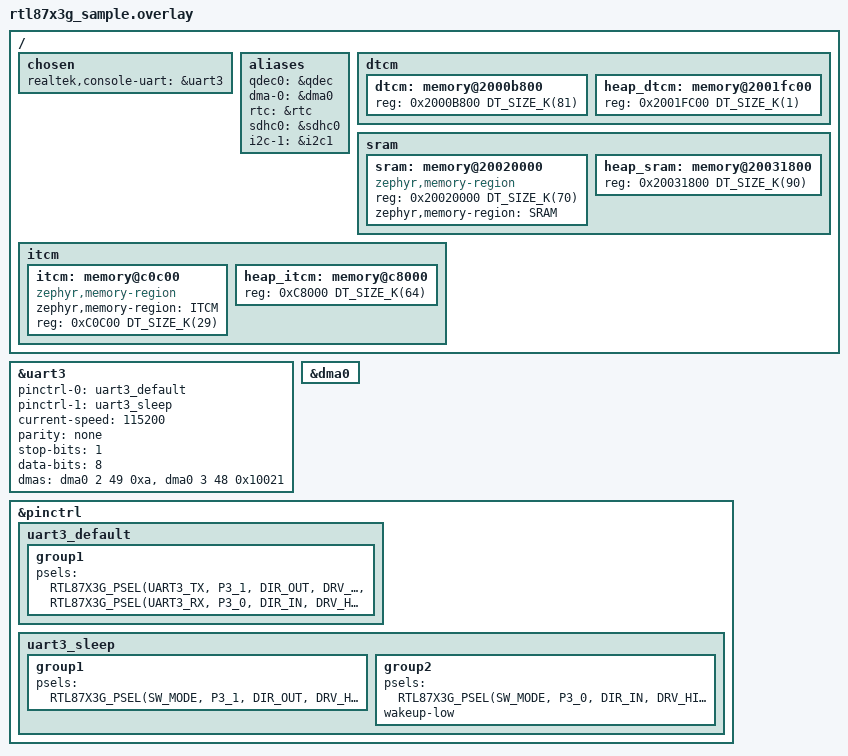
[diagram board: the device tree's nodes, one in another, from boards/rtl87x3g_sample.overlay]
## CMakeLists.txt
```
#
# Copyright (c) 2026, Realtek Semiconductor Corporation
#
# SPDX-License-Identifier: LicenseRef-Realtek-5-Clause
#

message(STATUS "CMAKELIST FOLDER: ${CMAKE_CURRENT_SOURCE_DIR}")

cmake_minimum_required(VERSION 3.20.0)

#===========version generation===========
include(${CMAKE_CURRENT_SOURCE_DIR}/../../cmake/version_generate.cmake)
generate_version()
#===========version generation===========
#===========post build===========
# post build should be called before find_package
include(${CMAKE_CURRENT_SOURCE_DIR}/../../cmake/post_build.cmake)
rtk_post_build()
#===========post build===========

find_package(Zephyr REQUIRED HINTS $ENV{ZEPHYR_BASE})
project(bt_pan_demo)

FILE(GLOB app_sources src/*.c src/pan_test/*.c src/pan_test/https/*.c)
target_sources(app PRIVATE
  ${app_sources}
  )

set(sources
   ${ZEPHYR_REALTEK_APP_MODULE_DIR}/common/console/transport/console_uart.c
   )

set(headers
    #header files from app
	  src/
    #header files from libs
    ${ZEPHYR_REALTEK_APP_MODULE_DIR}/../modules/hal/realtek/rtl87x3g/subsys/audio/inc
    ${ZEPHYR_REALTEK_APP_MODULE_DIR}/../modules/hal/realtek/rtl87x3g/subsys/console/inc
    ${ZEPHYR_REALTEK_APP_MODULE_DIR}/../modules/hal/realtek/rtl87x3g/subsys/lwip/src/arch
    ${ZEPHYR_REALTEK_APP_MODULE_DIR}/../modules/hal/realtek/rtl87x3g/subsys/lwip/src
    ${ZEPHYR_REALTEK_APP_MODULE_DIR}/../modules/hal/realtek/rtl87x3g/subsys/lwip/
    ${ZEPHYR_REALTEK_APP_MODULE_DIR}/../modules/hal/realtek/rtl87x3g/subsys/mbedtls/include/mbedtls
    ${ZEPHYR_REALTEK_APP_MODULE_DIR}/common/console/transport
    ${ZEPHYR_REALTEK_APP_MODULE_DIR}/samples/bt_pan_demo
    )  

foreach(header ${headers})
    if(EXISTS ${header})
        zephyr_include_directories(${header})
    else()
        message(FATAL_ERROR "header file directory does not exist: ${header}. Current cmakelist: ${CMAKE_CURRENT_SOURCE_DIR}")
    endif()
endforeach()

foreach(src ${sources})
    if(EXISTS ${src})
        target_sources(app PRIVATE ${src})
    else()
        message(FATAL_ERROR "source file does not exist: ${src}. Current cmakelist: ${CMAKE_CURRENT_SOURCE_DIR}")
    endif()
endforeach()
  
target_precompile_headers(app PUBLIC
	          ${CMAKE_CURRENT_SOURCE_DIR}/src/app_flags.h
			  )

target_include_directories(app PRIVATE src)
```

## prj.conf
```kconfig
# nothing here
CONFIG_SERIAL=y
CONFIG_UART_ASYNC_API=y
CONFIG_REALTEK_SUBSYS_SYSM=y
CONFIG_REALTEK_SUBSYS_CONSOLE=y
CONFIG_REALTEK_SUBSYS_REMOTE=y
CONFIG_REALTEK_SUBSYS_BTM=y
CONFIG_REALTEK_SUBSYS_AUDIO=y
CONFIG_REALTEK_SUBSYS_LWIP=y
CONFIG_REALTEK_SUBSYS_MBEDTLS=y
CONFIG_NEWLIB_LIBC=y
CONFIG_HEAP_MEM_POOL_SIZE=1024
```

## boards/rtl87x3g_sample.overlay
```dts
/*
 * Copyright(c) 2024, Realtek Semiconductor Corporation.
 *
 * SPDX-License-Identifier: Apache-2.0
 */

#include <zephyr/dt-bindings/gpio/realtek-rtl87x3g-gpio.h>
#include <zephyr/dt-bindings/pinctrl/rtl87x3g-pinctrl.h>

/ {
    chosen {
        /* Route the RTK console transport onto uart3 through the Zephyr async
         * UART driver. Change this phandle to move the console to any UART. */
        realtek,console-uart = &uart3;
    };
};

&uart3 {
    pinctrl-0 = <&uart3_default>;
    pinctrl-1 = <&uart3_sleep>;
    pinctrl-names = "default", "sleep";
    status = "okay";
    current-speed = <115200>;
    parity = "none";
    stop-bits = "1";
    data-bits = <8>;
    dmas = <&dma0 2 49 0xa>, <&dma0 3 48 0x10021>;
    dma-names = "rx", "tx";
};
 
&dma0 {
    status = "okay";
};
 
&pinctrl
{
    uart3_default:uart3_default {
        group1 {
            psels = <RTL87X3G_PSEL(UART3_TX, P3_1, DIR_OUT, DRV_HIGH, PULL_UP)>,
            <RTL87X3G_PSEL(UART3_RX, P3_0, DIR_IN, DRV_HIGH, PULL_UP)>;
        };
    };
 
    uart3_sleep:uart3_sleep {
        group1 {
            psels = <RTL87X3G_PSEL(SW_MODE, P3_1, DIR_OUT, DRV_HIGH, PULL_UP)>;
        };
        group2 {
            psels = <RTL87X3G_PSEL(SW_MODE, P3_0, DIR_IN, DRV_HIGH, PULL_UP)>;
            wakeup-low;
        };
    };
};

/*delete-node only support nodes with lable */
/delete-node/ &dtcm;
/delete-node/ &heap_dtcm;
/delete-node/ &sram;
/delete-node/ &heap_sram;
/delete-node/ &itcm;
/delete-node/ &heap_itcm;
/delete-node/ &dsp_share_ram;

/ {
	aliases {
		qdec0 = &qdec;
		dma-0 = &dma0;
		rtc = &rtc;
		sdhc0 = &sdhc0;
		i2c-1 = &i2c1;
    };


	
	/* DTCM addr: 0x20000000~0x20020000, total size: 128KByte.
	 * The front 46Kbyte was taken by RTK internal.
	 * If users wants to increase global variables and zephyr static heap,
	 * please follow the steps:
	 * 1. increase dtcm size value "reg = <0x2000B800 DT_SIZE_K(NEW_SIZE)>"
	 * 2. modify heap_dtcm addr label "heap_dtcm: memory@NEW_ADDR"
	 * 3. modify heap_dtcm reg addr "reg = <NEW_ADDR DT_SIZE_K(NEW_SIZE)>"
	 * 4. decrease heap_dtcm size value "reg = <NEW_ADDR DT_SIZE_K(NEW_SIZE)>"
	 * Warning: 
	 * 1. the dtcm address should NOT modified!
	 * 2. the dtcm plus heap_dtcm size should NOT exceed 82KByte!
	 */
	dtcm {
		dtcm: memory@2000b800 {
			device_type = "dtcm region";
			reg = <0x2000B800 DT_SIZE_K(81)>;
		};
		heap_dtcm: memory@2001fc00 {
			device_type = "heap dtcm region";
			reg = <0x2001FC00 DT_SIZE_K(1)>;
		};
	};
	/* sram addr: 0x20020000~0x20048000, total size: 160KByte.
	 * call zephyr_code_relocate(FILES xxx.x LOCATION SRAM) at cmakelist could relocate variables on sram. 
	 * for more information, please refer to https://docs.zephyrproject.org/latest/kernel/code-relocation.html
	 * If users wants to increase sram size, please follow the steps:
	 * 1. increase sram size value "reg = <0x20020000 DT_SIZE_K(NEW_SIZE)>"
	 * 2. modify heap_sram addr label "heap_sram: memory@NEW_ADDR"
	 * 3. modify heap_sram reg addr "reg = <NEW_ADDR DT_SIZE_K(NEW_SIZE)>"
	 * 4. decrease heap_sram size value "reg = <NEW_ADDR DT_SIZE_K(NEW_SIZE)>"
	 * Warning: 
	 * 1. the sram address should NOT modified!
	 * 2. the sram plus heap_sram size should NOT exceed 160KByte!
	 */
	sram {
		sram: memory@20020000 {
			device_type = "sram region";
			compatible = "zephyr,memory-region", "mmio-sram";
			reg = <0x20020000 DT_SIZE_K(70)>;
			zephyr,memory-region = "SRAM";
		};
		heap_sram: memory@20031800 {
			device_type = "heap sram region";
			reg = <0x20031800 DT_SIZE_K(90)>;
		};
	};

	itcm {
		itcm: memory@c0c00 {
			device_type = "itcm region";
			compatible = "zephyr,memory-region", "arm,itcm";
			zephyr,memory-region = "ITCM";
			reg = <0xC0C00 DT_SIZE_K(29)>;
		};
		heap_itcm: memory@c8000 {
			device_type = "heap itcm region";
			reg = <0xC8000 DT_SIZE_K(64)>;
		};
	};

/**
	dsp_ram {
		dsp_share_ram: memory@20048000 {
			compatible = "zephyr,memory-region";
			device_type = "dsp_share_ram region";
			zephyr,memory-region = "DSPRAM";
			reg = <0x20048000 DT_SIZE_K(80)>;
		};
	};
*/	
};
```

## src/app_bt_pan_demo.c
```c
/*
 * Copyright (c) 2026, Realtek Semiconductor Corporation
 *
 * SPDX-License-Identifier: LicenseRef-Realtek-5-Clause
 */

#include <string.h>
#include <stdlib.h>
#include "trace.h"
#include "console.h"
#include "os_mem.h"
#include "os_sched.h"
#include "pm.h"
#include "console.h"
#include "gap_br.h"
#include "btm.h"
#include "bt_types.h"
#include "bt_sdp.h"
#include "bt_pan.h"
#include "app_bt_pan_demo_link.h"
#include "app_bt_pan_demo.h"
#include "bnepif.h"
#include "lwip/tcpip.h"
#include "lwip/sockets.h"


extern uint8_t bd_addr_local[6];

#if F_APP_PAN_PANU_SUPPORT
static const uint8_t pan_panu_sdp_record[] =
{
    //total length
    SDP_DATA_ELEM_SEQ_HDR,
    0x76,//0x59,

    //Attribute SDP_ATTR_SRV_CLASS_ID_LIST
    SDP_UNSIGNED_TWO_BYTE,
    (uint8_t)(SDP_ATTR_SRV_CLASS_ID_LIST >> 8),
    (uint8_t)SDP_ATTR_SRV_CLASS_ID_LIST,
    SDP_DATA_ELEM_SEQ_HDR,
    0x03,
    SDP_UUID16_HDR,
    (uint8_t)(UUID_PANU >> 8),
    (uint8_t)(UUID_PANU),

    //attribute SDP_ATTR_PROTO_DESC_LIST
    SDP_UNSIGNED_TWO_BYTE,
    (uint8_t)(SDP_ATTR_PROTO_DESC_LIST >> 8),
    (uint8_t)SDP_ATTR_PROTO_DESC_LIST,
    SDP_DATA_ELEM_SEQ_HDR,
    0x1E,
    SDP_DATA_ELEM_SEQ_HDR,
    0x06,
    SDP_UUID16_HDR,
    (uint8_t)(UUID_L2CAP >> 8),
    (uint8_t)(UUID_L2CAP),
    SDP_UNSIGNED_TWO_BYTE,
    (uint8_t)(PSM_BNEP >> 8),
    (uint8_t)(PSM_BNEP),
    SDP_DATA_ELEM_SEQ_HDR,
    0x14,
    SDP_UUID16_HDR,
    (uint8_t)(UUID_BNEP >> 8),
    (uint8_t)(UUID_BNEP),
    SDP_UNSIGNED_TWO_BYTE,
    0x01,
    0x00,
    SDP_DATA_ELEM_SEQ_HDR,
    0x0C,
    SDP_UNSIGNED_TWO_BYTE,
    0x08,
    0x00,
    SDP_UNSIGNED_TWO_BYTE,
    0x08,
    0x06,
    SDP_UNSIGNED_TWO_BYTE,
    0x81,
    0x00,
    SDP_UNSIGNED_TWO_BYTE,
    0x86,
    0xdd,

    //attribute SDP_ATTR_BROWSE_GROUP_LIST
    SDP_UNSIGNED_TWO_BYTE,
    (uint8_t)(SDP_ATTR_BROWSE_GROUP_LIST >> 8),
    (uint8_t)SDP_ATTR_BROWSE_GROUP_LIST,
    SDP_DATA_ELEM_SEQ_HDR,
    0x03,
    SDP_UUID16_HDR,
    (uint8_t)(UUID_PUBLIC_BROWSE_GROUP >> 8),
    (uint8_t)(UUID_PUBLIC_BROWSE_GROUP),

    //Attribute SDP_ATTR_LANG_BASE_ATTR_ID_LIST
    SDP_UNSIGNED_TWO_BYTE,
    (uint8_t)(SDP_ATTR_LANG_BASE_ATTR_ID_LIST >> 8),
    (uint8_t)SDP_ATTR_LANG_BASE_ATTR_ID_LIST,
    SDP_DATA_ELEM_SEQ_HDR,
    0x09,
    SDP_UNSIGNED_TWO_BYTE,
    (uint8_t)(SDP_LANG_ENGLISH >> 8),
    (uint8_t)(SDP_LANG_ENGLISH),
    SDP_UNSIGNED_TWO_BYTE,
    (uint8_t)(SDP_CHARACTER_UTF8 >> 8),
    (uint8_t)(SDP_CHARACTER_UTF8),
    SDP_UNSIGNED_TWO_BYTE,
    (uint8_t)(SDP_BASE_LANG_OFFSET >> 8),
    (uint8_t)(SDP_BASE_LANG_OFFSET),

    //attribute SDP_ATTR_PROFILE_DESC_LIST
    SDP_UNSIGNED_TWO_BYTE,
    (uint8_t)(SDP_ATTR_PROFILE_DESC_LIST >> 8),
    (uint8_t)SDP_ATTR_PROFILE_DESC_LIST,
    SDP_DATA_ELEM_SEQ_HDR,
    0x08,
    SDP_DATA_ELEM_SEQ_HDR,
    0x06,
    SDP_UUID16_HDR,
    (uint8_t)(UUID_PANU >> 8),
    (uint8_t)(UUID_PANU),
    SDP_UNSIGNED_TWO_BYTE,
    (uint8_t)(0x0100 >> 8),
    (uint8_t)(0x0100),

    //Attribute SDP_ATTR_SRV_NAME
    SDP_UNSIGNED_TWO_BYTE,
    (uint8_t)((SDP_ATTR_SRV_NAME + SDP_BASE_LANG_OFFSET) >> 8),
    (uint8_t)(SDP_ATTR_SRV_NAME + SDP_BASE_LANG_OFFSET),
    SDP_STRING_HDR,
    0x0C,
    'R', 'e', 'a', 'l', 't', 'e', 'k', ' ', 'P', 'A', 'N', 'U',

    //Attribute SDP_ATTR_SRV_DESC
    SDP_UNSIGNED_TWO_BYTE,
    (uint8_t)((SDP_ATTR_SRV_DESC + SDP_BASE_LANG_OFFSET) >> 8),
    (uint8_t)(SDP_ATTR_SRV_DESC + SDP_BASE_LANG_OFFSET),
    SDP_STRING_HDR,
    0x0C,
    'R', 'e', 'a', 'l', 't', 'e', 'k', ' ', 'P', 'A', 'N', 'U',

    //Attribute SDP_ATTR_SECURITY_DESC
    SDP_UNSIGNED_TWO_BYTE,
    (uint8_t)(SDP_ATTR_SECURITY_DESC >> 8),
    (uint8_t)SDP_ATTR_SECURITY_DESC,
    SDP_UNSIGNED_TWO_BYTE,
    0x00,
    0x00
};
#endif

#if F_APP_PAN_NAP_SUPPORT
static const uint8_t pan_nap_sdp_record[] =
{
    //total length
    SDP_DATA_ELEM_SEQ_HDR,
    0x82,//0x59,

    //Attribute SDP_ATTR_SRV_CLASS_ID_LIST
    SDP_UNSIGNED_TWO_BYTE,
    (uint8_t)(SDP_ATTR_SRV_CLASS_ID_LIST >> 8),
    (uint8_t)SDP_ATTR_SRV_CLASS_ID_LIST,
    SDP_DATA_ELEM_SEQ_HDR,
    0x03,
    SDP_UUID16_HDR,
    (uint8_t)(UUID_NAP >> 8),
    (uint8_t)(UUID_NAP),

    //attribute SDP_ATTR_PROTO_DESC_LIST
    SDP_UNSIGNED_TWO_BYTE,
    (uint8_t)(SDP_ATTR_PROTO_DESC_LIST >> 8),
    (uint8_t)SDP_ATTR_PROTO_DESC_LIST,
    SDP_DATA_ELEM_SEQ_HDR,
    0x1B,
    SDP_DATA_ELEM_SEQ_HDR,
    0x06,
    SDP_UUID16_HDR,
    (uint8_t)(UUID_L2CAP >> 8),
    (uint8_t)(UUID_L2CAP),
    SDP_UNSIGNED_TWO_BYTE,
    (uint8_t)(PSM_BNEP >> 8),
    (uint8_t)(PSM_BNEP),
    SDP_DATA_ELEM_SEQ_HDR,
    0x11,
    SDP_UUID16_HDR,
    (uint8_t)(UUID_BNEP >> 8),
    (uint8_t)(UUID_BNEP),
    SDP_UNSIGNED_TWO_BYTE,
    0x01,
    0x00,
    SDP_DATA_ELEM_SEQ_HDR,
    0x09,
    SDP_UNSIGNED_TWO_BYTE,
    0x08,
    0x00,
    SDP_UNSIGNED_TWO_BYTE,
    0x08,
    0x06,
    SDP_UNSIGNED_TWO_BYTE,
    0x81,
    0x00,
    SDP_UNSIGNED_TWO_BYTE,
    0x86,
    0xdd,

    //attribute SDP_ATTR_BROWSE_GROUP_LIST
    SDP_UNSIGNED_TWO_BYTE,
    (uint8_t)(SDP_ATTR_BROWSE_GROUP_LIST >> 8),
    (uint8_t)SDP_ATTR_BROWSE_GROUP_LIST,
    SDP_DATA_ELEM_SEQ_HDR,
    0x03,
    SDP_UUID16_HDR,
    (uint8_t)(UUID_PUBLIC_BROWSE_GROUP >> 8),
    (uint8_t)(UUID_PUBLIC_BROWSE_GROUP),

    //Attribute SDP_ATTR_LANG_BASE_ATTR_ID_LIST
    SDP_UNSIGNED_TWO_BYTE,
    (uint8_t)(SDP_ATTR_LANG_BASE_ATTR_ID_LIST >> 8),
    (uint8_t)SDP_ATTR_LANG_BASE_ATTR_ID_LIST,
    SDP_DATA_ELEM_SEQ_HDR,
    0x09,
    SDP_UNSIGNED_TWO_BYTE,
    (uint8_t)(SDP_LANG_ENGLISH >> 8),
    (uint8_t)(SDP_LANG_ENGLISH),
    SDP_UNSIGNED_TWO_BYTE,
    (uint8_t)(SDP_CHARACTER_UTF8 >> 8),
    (uint8_t)(SDP_CHARACTER_UTF8),
    SDP_UNSIGNED_TWO_BYTE,
    (uint8_t)(SDP_BASE_LANG_OFFSET >> 8),
    (uint8_t)(SDP_BASE_LANG_OFFSET),

    //attribute SDP_ATTR_PROFILE_DESC_LIST
    SDP_UNSIGNED_TWO_BYTE,
    (uint8_t)(SDP_ATTR_PROFILE_DESC_LIST >> 8),
    (uint8_t)SDP_ATTR_PROFILE_DESC_LIST,
    SDP_DATA_ELEM_SEQ_HDR,
    0x08,
    SDP_DATA_ELEM_SEQ_HDR,
    0x06,
    SDP_UUID16_HDR,
    (uint8_t)(UUID_NAP >> 8),
    (uint8_t)(UUID_NAP),
    SDP_UNSIGNED_TWO_BYTE,
    (uint8_t)(0x0100 >> 8),
    (uint8_t)(0x0100),

    //Attribute SDP_ATTR_SRV_NAME
    SDP_UNSIGNED_TWO_BYTE,
    (uint8_t)((SDP_ATTR_SRV_NAME + SDP_BASE_LANG_OFFSET) >> 8),
    (uint8_t)(SDP_ATTR_SRV_NAME + SDP_BASE_LANG_OFFSET),
    SDP_STRING_HDR,
    0x0B,
    'R', 'e', 'a', 'l', 't', 'e', 'k', ' ', 'N', 'A', 'P',

    //Attribute SDP_ATTR_SRV_DESC
    SDP_UNSIGNED_TWO_BYTE,
    (uint8_t)((SDP_ATTR_SRV_DESC + SDP_BASE_LANG_OFFSET) >> 8),
    (uint8_t)(SDP_ATTR_SRV_DESC + SDP_BASE_LANG_OFFSET),
    SDP_STRING_HDR,
    0x0B,
    'R', 'e', 'a', 'l', 't', 'e', 'k', ' ', 'N', 'A', 'P',

    //Attribute SDP_ATTR_SECURITY_DESC
    SDP_UNSIGNED_TWO_BYTE,
    (uint8_t)(SDP_ATTR_SECURITY_DESC >> 8),
    (uint8_t)SDP_ATTR_SECURITY_DESC,
    SDP_UNSIGNED_TWO_BYTE,
    0x00,
    0x01,

    //Attribute SDP_ATTR_NET_ACCESS_TYPE
    SDP_UNSIGNED_TWO_BYTE,
    (uint8_t)(SDP_ATTR_NET_ACCESS_TYPE >> 8),
    (uint8_t)SDP_ATTR_NET_ACCESS_TYPE,
    SDP_UNSIGNED_TWO_BYTE,
    0x00,
    0x05,

    //Attribute SDP_ATTR_MAX_NET_ACCESS_RATE
    SDP_UNSIGNED_TWO_BYTE,
    (uint8_t)(SDP_ATTR_MAX_NET_ACCESS_RATE >> 8),
    (uint8_t)SDP_ATTR_MAX_NET_ACCESS_RATE,
    SDP_UNSIGNED_FOUR_BYTE,
    0x00,
    0x13,
    0x12,
    0xd0
};
#endif

#if F_APP_PAN_GN_SUPPORT
static const uint8_t pan_gn_sdp_record[] =
{
    //total length
    SDP_DATA_ELEM_SEQ_HDR,
    0x77,//0x59,

    //Attribute SDP_ATTR_SRV_CLASS_ID_LIST
    SDP_UNSIGNED_TWO_BYTE,
    (uint8_t)(SDP_ATTR_SRV_CLASS_ID_LIST >> 8),
    (uint8_t)SDP_ATTR_SRV_CLASS_ID_LIST,
    SDP_DATA_ELEM_SEQ_HDR,
    0x03,
    SDP_UUID16_HDR,
    (uint8_t)(UUID_GN >> 8),
    (uint8_t)(UUID_GN),

    //attribute SDP_ATTR_PROTO_DESC_LIST
    SDP_UNSIGNED_TWO_BYTE,
    (uint8_t)(SDP_ATTR_PROTO_DESC_LIST >> 8),
    (uint8_t)SDP_ATTR_PROTO_DESC_LIST,
    SDP_DATA_ELEM_SEQ_HDR,
    0x1B,
    SDP_DATA_ELEM_SEQ_HDR,
    0x06,
    SDP_UUID16_HDR,
    (uint8_t)(UUID_L2CAP >> 8),
    (uint8_t)(UUID_L2CAP),
    SDP_UNSIGNED_TWO_BYTE,
    (uint8_t)(PSM_BNEP >> 8),
    (uint8_t)(PSM_BNEP),
    SDP_DATA_ELEM_SEQ_HDR,
    0x11,
    SDP_UUID16_HDR,
    (uint8_t)(UUID_BNEP >> 8),
    (uint8_t)(UUID_BNEP),
    SDP_UNSIGNED_TWO_BYTE,
    0x01,
    0x00,
    SDP_DATA_ELEM_SEQ_HDR,
    0x09,
    SDP_UNSIGNED_TWO_BYTE,
    0x08,
    0x00,
    SDP_UNSIGNED_TWO_BYTE,
    0x08,
    0x06,
    SDP_UNSIGNED_TWO_BYTE,
    0x81,
    0x00,
    SDP_UNSIGNED_TWO_BYTE,
    0x86,
    0xdd,

    //attribute SDP_ATTR_BROWSE_GROUP_LIST
    SDP_UNSIGNED_TWO_BYTE,
    (uint8_t)(SDP_ATTR_BROWSE_GROUP_LIST >> 8),
    (uint8_t)SDP_ATTR_BROWSE_GROUP_LIST,
    SDP_DATA_ELEM_SEQ_HDR,
    0x03,
    SDP_UUID16_HDR,
    (uint8_t)(UUID_PUBLIC_BROWSE_GROUP >> 8),
    (uint8_t)(UUID_PUBLIC_BROWSE_GROUP),

    //Attribute SDP_ATTR_LANG_BASE_ATTR_ID_LIST
    SDP_UNSIGNED_TWO_BYTE,
    (uint8_t)(SDP_ATTR_LANG_BASE_ATTR_ID_LIST >> 8),
    (uint8_t)SDP_ATTR_LANG_BASE_ATTR_ID_LIST,
    SDP_DATA_ELEM_SEQ_HDR,
    0x09,
    SDP_UNSIGNED_TWO_BYTE,
    (uint8_t)(SDP_LANG_ENGLISH >> 8),
    (uint8_t)(SDP_LANG_ENGLISH),
    SDP_UNSIGNED_TWO_BYTE,
    (uint8_t)(SDP_CHARACTER_UTF8 >> 8),
    (uint8_t)(SDP_CHARACTER_UTF8),
    SDP_UNSIGNED_TWO_BYTE,
    (uint8_t)(SDP_BASE_LANG_OFFSET >> 8),
    (uint8_t)(SDP_BASE_LANG_OFFSET),

    //Attribute SDP_ATTR_SRV_AVAILABILITY
    SDP_UNSIGNED_TWO_BYTE,
    (uint8_t)(SDP_ATTR_SRV_AVAILABILITY >> 8),
    (uint8_t)SDP_ATTR_SRV_AVAILABILITY,
    SDP_UNSIGNED_ONE_BYTE,
    0xff,

    //attribute SDP_ATTR_PROFILE_DESC_LIST
    SDP_UNSIGNED_TWO_BYTE,
    (uint8_t)(SDP_ATTR_PROFILE_DESC_LIST >> 8),
    (uint8_t)SDP_ATTR_PROFILE_DESC_LIST,
    SDP_DATA_ELEM_SEQ_HDR,
    0x08,
    SDP_DATA_ELEM_SEQ_HDR,
    0x06,
    SDP_UUID16_HDR,
    (uint8_t)(UUID_GN >> 8),
    (uint8_t)(UUID_GN),
    SDP_UNSIGNED_TWO_BYTE,
    (uint8_t)(0x0100 >> 8),
    (uint8_t)(0x0100),

    //Attribute SDP_ATTR_SRV_NAME
    SDP_UNSIGNED_TWO_BYTE,
    (uint8_t)((SDP_ATTR_SRV_NAME + SDP_BASE_LANG_OFFSET) >> 8),
    (uint8_t)(SDP_ATTR_SRV_NAME + SDP_BASE_LANG_OFFSET),
    SDP_STRING_HDR,
    0x0A,
    'R', 'e', 'a', 'l', 't', 'e', 'k', ' ', 'G', 'N',

    //Attribute SDP_ATTR_SRV_DESC
    SDP_UNSIGNED_TWO_BYTE,
    (uint8_t)((SDP_ATTR_SRV_DESC + SDP_BASE_LANG_OFFSET) >> 8),
    (uint8_t)(SDP_ATTR_SRV_DESC + SDP_BASE_LANG_OFFSET),
    SDP_STRING_HDR,
    0x0A,
    'R', 'e', 'a', 'l', 't', 'e', 'k', ' ', 'G', 'N',

    //Attribute SDP_ATTR_SECURITY_DESC
    SDP_UNSIGNED_TWO_BYTE,
    (uint8_t)(SDP_ATTR_SECURITY_DESC >> 8),
    (uint8_t)SDP_ATTR_SECURITY_DESC,
    SDP_UNSIGNED_TWO_BYTE,
    0x00,
    0x01
};
#endif

static void app_bt_pan_demo_cback(T_BT_PAN_EVENT event_type, void *event_buf, uint16_t buf_len)
{
    T_BT_PAN_EVENT_PARAM *param = event_buf;
    T_APP_BT_PAN_DEMO_LINK *p_link;

    switch (event_type)
    {
    case BT_PAN_EVENT_CONN_IND:
        p_link = app_bt_pan_demo_find_link(param->pan_conn_ind.bd_addr);
        if (p_link != NULL)
        {
            bt_pan_connect_cfm(app_db.local_addr, p_link->bd_addr, true);
        }
        break;

    case BT_PAN_EVENT_SETUP_CONN_IND:
        p_link = app_bt_pan_demo_find_link(param->pan_conn_ind.bd_addr);
        if (p_link != NULL)
        {
            bt_pan_setup_connection_rsp(p_link->bd_addr, 0);
        }
        break;

    case BT_PAN_EVENT_CONN_CMPL:
        {
            char *temp_buff = "PAN Connected!\r\n";
            console_write((uint8_t *)temp_buff, strlen(temp_buff));
            p_link = app_bt_pan_demo_find_link(param->pan_conn_cmpl.bd_addr);
            if (p_link != NULL)
            {
                memcpy(app_db.remote_addr, param->pan_conn_cmpl.bd_addr, 6);
            }

            bnepif_netif_up(app_db.remote_addr);
            bnepif_dhcp_start();
        }

        break;

    case BT_PAN_EVENT_DISCONN_CMPL:
        {
            char *temp_buff = "PAN Disconnected!\r\n";
            console_write((uint8_t *)temp_buff, strlen(temp_buff));
            bnepif_netif_down();
        }
        break;

    case BT_PAN_EVENT_ETHERNET_PACKET_IND:
        APP_PRINT_TRACE1("app_bt_pan_demo_cback: BT_PAN_EVENT_ETHERNET_PACKET_IND len 0x%x",
                         param->pan_ethernet_packet_ind.len);
        bnepif_low_level_input(param->pan_ethernet_packet_ind.buf, param->pan_ethernet_packet_ind.len);
        break;

    default:
        break;
    }
}

void app_bt_pan_demo_init(void)
{
    int32_t ret = 0;
#if F_APP_PAN_PANU_SUPPORT
    if (bt_sdp_record_add((void *)pan_panu_sdp_record) == false)
    {
        ret = -1;
        goto fail_sdp_add;
    }
#endif

#if F_APP_PAN_NAP_SUPPORT
    if (bt_sdp_record_add((void *)pan_nap_sdp_record) == false)
    {
        ret = -1;
        goto fail_sdp_add;
    }
#endif

#if F_APP_PAN_GN_SUPPORT
    if (bt_sdp_record_add((void *)pan_gn_sdp_record) == false)
    {
        ret = -1;
        goto fail_sdp_add;
    }
#endif

    if (bt_pan_init() == false)
    {
        ret = 2;
        goto fail_init;
    }

    bt_pan_cback_register(app_bt_pan_demo_cback);

    tcpip_init(NULL, NULL);
    bnepif_init(bd_addr_local, bt_pan_send);

    return;

fail_init:
fail_sdp_add:
    APP_PRINT_ERROR1("app_bt_pan_demo_init: failed %d", ret);
}

bool app_bt_pan_demo_connect(uint8_t *bd_addr)
{
    T_BT_SDP_UUID_DATA uuid;

    uuid.uuid_16 = UUID_NAP;

    return bt_sdp_discov_start(bd_addr, BT_SDP_UUID16, uuid);
}

bool app_bt_pan_demo_disconnect(uint8_t *bd_addr)
{
    T_APP_BT_PAN_DEMO_LINK *p_link;

    p_link = app_bt_pan_demo_find_link(bd_addr);
    if (p_link != NULL)
    {
        return bt_pan_disconnect_req(bd_addr);
    }

    return false;
}

bool app_bt_pan_demo_setup_onn_rsp(uint8_t *bd_addr)
{
    return bt_pan_setup_connection_rsp(bd_addr, 0x00);
}

bool app_bt_pan_demo_filter_net_type_set(uint8_t *bd_addr)
{
    uint16_t start_array[] = {0x86dd};
    uint16_t end_array[] = {0x86dd};

    return bt_pan_filter_net_type_set(bd_addr, 1, start_array, end_array);
}

bool app_bt_pan_demo_filter_multi_addr_set(uint8_t *bd_addr)
{
    uint8_t start_array[][6] = {{0x03, 0x00, 0x00, 0x20, 0x00, 0x00}};
    uint8_t end_array[][6] = {{0x03, 0x00, 0x00, 0x20, 0x00, 0x00}};

    return bt_pan_filter_multi_addr_set(bd_addr, 1, start_array, end_array);
}

bool app_bt_pan_demo_send(uint8_t *bd_addr, uint8_t type)
{
    uint8_t  buf[36] = {0x03, 0x00, 0x3c, 0x3b, 0x3a, 0x39, 0x38, 0x37, 0x36, 0x35, 0x34, 0x33, 0x32, 0x31, 0x30, 0x2f, 0x2e, 0x2d, 0x2c, 0x2b, 0x2a, 0x29, 0x28, 0x27, 0x26, 0x25, 0x24, 0x23, 0x22, 0x21, 0x20, 0x1f, 0x1e, 0x1d, 0x1c, 0x1b};
    uint8_t  addr[6] = {0};
    uint8_t *new_buf;

    new_buf = calloc(1, 48);
    if (new_buf == NULL)
    {
        return false;
    }

    if (type == 0)
    {
        memcpy(new_buf, addr, 6);
        memcpy(new_buf + 6, addr, 6);
        memcpy(new_buf + 12, buf, 36);
    }

    if (type == 2)
    {
        memcpy(new_buf, app_db.remote_addr, 6);
        memcpy(new_buf + 6, app_db.local_addr, 6);
        memcpy(new_buf + 12, buf, 36);
    }

    if (type == 3)
    {
        memcpy(new_buf, app_db.remote_addr, 6);
        memcpy(new_buf + 6, addr, 6);
        memcpy(new_buf + 12, buf, 36);
    }

    if (type == 4)
    {
        memcpy(new_buf, addr, 6);
        memcpy(new_buf + 6, app_db.local_addr, 6);
        memcpy(new_buf + 12, buf, 36);
    }

    bt_pan_send(bd_addr, new_buf, 46);
    free(new_buf);
    return true;
}

bool app_bt_pan_demo_arp(uint8_t *bd_addr)
{
    uint8_t  buf[42] = {0xff, 0xff, 0xff, 0xff, 0xff, 0xff, 0x13, 0x22, 0x56, 0xab, 0xbc, 0xdd, 0x08, 0x06, 0x00, 0x01, 0x08, 0x00, 0x06, 0x04, 0x00, 0x01, 0x13, 0x22, 0x56, 0xab, 0xbc, 0xdd, 0xc0, 0xa8, 0xa7, 0x98, 0x00, 0x00, 0x00, 0x00, 0x00, 0x00, 0xc0, 0xa8, 0xa8, 0x64};

    bt_pan_send(bd_addr, buf, 42);
    return true;
}

bool app_bt_pan_demo_arp_v6(uint8_t *bd_addr)
{
    uint8_t  buf[86] = {0xff, 0xff, 0xff, 0xff, 0xff, 0xff, 0xdd, 0xbc, 0xab, 0x56, 0x22, 0x13, 0x86, 0xdd, 0x60, 0x00, 0x00, 0x00, 0x00, 0x20, 0x3a, 0xff, 0xfe, 0x80, 0x00, 0x00, 0x00, 0x00, 0x00, 0x00, 0x5d, 0x89, 0xed, 0xde, 0x11, 0x07, 0xee, 0x5d, 0xfe, 0x80, 0x00, 0x00, 0x00, 0x00, 0x00, 0x00, 0x12, 0x34, 0xed, 0xde, 0x11, 0x07, 0x11, 0x5d, 0x87, 0x00, 0x73, 0x2a, 0x00, 0x00, 0x00, 0x00, 0xfe, 0x80, 0x00, 0x00, 0x00, 0x00, 0x00, 0x00, 0x12, 0x34, 0xed, 0xde, 0x11, 0x07, 0x11, 0x5d, 0x01, 0x01, 0x13, 0x22, 0x56, 0xab, 0xbc, 0xdd};

    bt_pan_send(bd_addr, buf, 86);
    return true;
}

bool app_bt_pan_demo_ping(uint8_t *bd_addr)
{
    uint8_t  buf[54] = {0x00, 0x1b, 0xdc, 0x08, 0xe5, 0xa9, 0xdd, 0xbc, 0xab, 0x56, 0x22, 0x13, 0x08, 0x00, 0x45, 0x00, 0x00, 0x28, 0x00, 0x29, 0x00, 0x00, 0x80, 0x01, 0x69, 0x5e, 0xc0, 0xa8, 0xa7, 0x98, 0xc0, 0xa8, 0xa8, 0x64, 0x08, 0x00, 0x87, 0x85, 0x00, 0x01, 0x00, 0x09, 0x50, 0x74, 0x73, 0x50, 0x74, 0x73, 0x50, 0x74, 0x73, 0x50, 0x74, 0x73};

    bt_pan_send(bd_addr, buf, 54);
    return true;
}

bool app_bt_pan_demo_ping_v6(uint8_t *bd_addr)
{
    uint8_t  buf[62] = {0x00, 0x1b, 0xdc, 0x08, 0xe5, 0xa9, 0xdd, 0xbc, 0xab, 0x56, 0x22, 0x13, 0x86, 0xdd, 0x60, 0x00, 0x00, 0x00, 0x00, 0x30, 0x3a, 0x01, 0xfe, 0x80, 0x00, 0x00, 0x00, 0x00, 0x00, 0x00, 0x5d, 0x89, 0xed, 0xde, 0x11, 0x07, 0xee, 0x5d, 0xfe, 0x80, 0x00, 0x00, 0x00, 0x00, 0x00, 0x00, 0x12, 0x34, 0xed, 0xde, 0x11, 0x07, 0x11, 0x5d, 0x08, 0x00, 0x00, 0x00, 0x00, 0x01, 0x00, 0x09};

    bt_pan_send(bd_addr, buf, 62);
    return true;
}

bool app_bt_pan_demo_ping_reply(uint8_t *bd_addr)
{
    uint8_t  buf[54] = {0x00, 0x1b, 0xdc, 0x08, 0xe5, 0xa9, 0xdd, 0xbc, 0xab, 0x56, 0x22, 0x13, 0x08, 0x00, 0x45, 0x00, 0x00, 0x28, 0x00, 0x29, 0x00, 0x00, 0x80, 0x01, 0x69, 0x5e, 0xc0, 0xa8, 0xa7, 0x98, 0xc0, 0xa8, 0xa8, 0x64, 0x00, 0x00, 0x8f, 0x85, 0x00, 0x01, 0x00, 0x09, 0x50, 0x74, 0x73, 0x50, 0x74, 0x73, 0x50, 0x74, 0x73, 0x50, 0x74, 0x73};

    bt_pan_send(bd_addr, buf, 54);
    return true;
}

bool app_bt_pan_demo_ping_reply_v6(uint8_t *bd_addr)
{
    uint8_t  buf[62] = {0x00, 0x1b, 0xdc, 0x08, 0xe5, 0xa9, 0xdd, 0xbc, 0xab, 0x56, 0x22, 0x13, 0x86, 0xdd, 0x60, 0x00, 0x00, 0x00, 0x00, 0x3c, 0x3a, 0x01, 0xfe, 0x80, 0x00, 0x00, 0x00, 0x00, 0x00, 0x00, 0x5d, 0x89, 0xed, 0xde, 0x11, 0x07, 0xee, 0x5d, 0xfe, 0x80, 0x00, 0x00, 0x00, 0x00, 0x00, 0x00, 0x12, 0x34, 0xed, 0xde, 0x11, 0x07, 0x11, 0x5d, 0x00, 0x00, 0x00, 0x00, 0x00, 0x01, 0x00, 0x09};

    bt_pan_send(bd_addr, buf, 62);
    return true;
}
```

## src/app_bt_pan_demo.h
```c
/*
 * Copyright (c) 2026, Realtek Semiconductor Corporation
 *
 * SPDX-License-Identifier: LicenseRef-Realtek-5-Clause
 */

#ifndef _APP_BT_PAN_DEMO_H_
#define _APP_BT_PAN_DEMO_H_

#include "app_msg.h"

#ifdef __cplusplus
extern "C" {
#endif /* __cplusplus */

/** @defgroup APP_BT_PAN_DEMO BT PAN Demo
* @brief APP BT PAN Demo
* @{
*/

/*============================================================================*
 *                         Macros
 *============================================================================*/
/** @addtogroup APP_BT_PAN_DEMO_Exported_Macros BT PAN Demo Exported Macros
  * @brief
  * @{
  */



/** End of APP_BT_PAN_DEMO_Exported_Macros
* @}
*/

/*============================================================================*
 *                         Functions
 *============================================================================*/
/** @defgroup APP_BT_PAN_DEMO_Exported_Functions BT PAN Demo Exported Functions
  * @brief
  * @{
  */

void app_bt_pan_demo_init(void);

bool app_bt_pan_demo_connect(uint8_t *bd_addr);

bool app_bt_pan_demo_disconnect(uint8_t *bd_addr);

bool app_bt_pan_demo_setup_onn_rsp(uint8_t *bd_addr);

bool app_bt_pan_demo_filter_net_type_set(uint8_t *bd_addr);

bool app_bt_pan_demo_filter_multi_addr_set(uint8_t *bd_addr);

bool app_bt_pan_demo_send(uint8_t *bd_addr, uint8_t type);

bool app_bt_pan_demo_arp(uint8_t *bd_addr);

bool app_bt_pan_demo_arp_v6(uint8_t *bd_addr);

bool app_bt_pan_demo_ping(uint8_t *bd_addr);

bool app_bt_pan_demo_ping_v6(uint8_t *bd_addr);

bool app_bt_pan_demo_ping_reply(uint8_t *bd_addr);

bool app_bt_pan_demo_ping_reply_v6(uint8_t *bd_addr);

/** @} End of APP_BT_PAN_DEMO_Exported_Functions */

/** @} End of APP_BT_PAN_DEMO */

#ifdef __cplusplus
}
#endif /* __cplusplus */

#endif /* _APP_BT_PAN_DEMO_H_ */
```

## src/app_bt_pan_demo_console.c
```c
/*
 * Copyright (c) 2026, Realtek Semiconductor Corporation
 *
 * SPDX-License-Identifier: LicenseRef-Realtek-5-Clause
 */

#include <stdio.h>
#include <stdint.h>
#include <stdbool.h>
#include <string.h>
#include <stdlib.h>
#include "os_mem.h"
#include "cli.h"
#include "bt_types.h"
#include "app_io_msg.h"
#include "app_bt_pan_demo_console.h"

bool app_bt_pan_demo_send_msg(T_IO_CONSOLE subtype, void *param_buf)
{
    T_IO_MSG msg;

    msg.type    = IO_MSG_TYPE_CONSOLE;
    msg.subtype = subtype;
    msg.u.buf   = param_buf;

    return app_io_send_msg(&msg);
}

bool console_pan(const char *cmd_str, char *buf, size_t buf_len)
{
    char       *subcmd;
    char       *p_param;
    int32_t     param_num;
    uint32_t    param_len;
    uint8_t     action;
    uint8_t     addr[6];
    uint8_t     i;
    void       *param_buf;

    param_num = cli_param_num_get(cmd_str);
    if (param_num < 1)
    {
        subcmd = (char *)cmd_str;
        goto err;
    }

    subcmd = (char *)cli_param_get(cmd_str, 1, &param_len);
    subcmd[param_len] = '\0';
    p_param = subcmd + param_len + 1;

    if (!strcmp(subcmd, "connect"))
    {
        if (param_num != 7)
        {
            goto err;
        }

        for (i = 0; i < 6; i++)
        {
            addr[i] = (uint8_t)strtol(cli_param_get(p_param, i, &param_len), NULL, 0);
        }

        action = BT_PAN_DEMO_ACTION_PAN_CONNECT;
    }
    else if (!strcmp(subcmd, "disconnect"))
    {
        action = BT_PAN_DEMO_ACTION_PAN_DISCONNECT;
    }
    else if (!strcmp(subcmd, "setup_conn_rsp"))
    {
        action = BT_PAN_DEMO_ACTION_PAN_SETUP_CONN_RSP;
    }
    else if (!strcmp(subcmd, "net_type_filter_set"))
    {
        action = BT_PAN_DEMO_ACTION_PAN_NET_TYPE_FILTER_SET;
    }
    else if (!strcmp(subcmd, "multi_addr_filter_set"))
    {
        action = BT_PAN_DEMO_ACTION_PAN_MULTI_ADDR_FILTER_SET;
    }
    else if (!strcmp(subcmd, "send_general"))
    {
        action = BT_PAN_DEMO_ACTION_PAN_SNED_GENERAL;
    }
    else if (!strcmp(subcmd, "send_compressed"))
    {
        action = BT_PAN_DEMO_ACTION_PAN_SNED_COMPRESSED;
    }
    else if (!strcmp(subcmd, "send_src_only"))
    {
        action = BT_PAN_DEMO_ACTION_PAN_SNED_SRC_ONLY;
    }
    else if (!strcmp(subcmd, "send_dst_only"))
    {
        action = BT_PAN_DEMO_ACTION_PAN_SNED_DST_ONLY;
    }
    else if (!strcmp(subcmd, "arp"))
    {
        action = BT_PAN_DEMO_ACTION_PAN_ARP;
    }
    else if (!strcmp(subcmd, "arp_v6"))
    {
        action = BT_PAN_DEMO_ACTION_PAN_ARP_V6;
    }
    else if (!strcmp(subcmd, "ping"))
    {
#include "pan_test/ping.h"
        char *server_name = (char *)cli_param_get(p_param, 0, &param_len);
        app_bt_pan_set_ping(server_name, param_len);
        action = BT_PAN_DEMO_ACTION_PAN_PING;
    }
    else if (!strcmp(subcmd, "ping_v6"))
    {
        action = BT_PAN_DEMO_ACTION_PAN_PING_V6;
    }
    else if (!strcmp(subcmd, "ping_reply"))
    {
        action = BT_PAN_DEMO_ACTION_PAN_PING_REPLY;
    }
    else if (!strcmp(subcmd, "ping_reply_v6"))
    {
        action = BT_PAN_DEMO_ACTION_PAN_PING_REPLY_V6;
    }
    else if (!strcmp(subcmd, "http"))
    {
#include "pan_test/http.h"
        uint32_t ip_str_len = 0, uri_len = 0;
        char *ip_str = (char *)cli_param_get(p_param, 0, &ip_str_len);
        uint16_t port = (uint16_t)strtol(cli_param_get(p_param, 1, &param_len), NULL, 0);
        char *uri = (char *)cli_param_get(p_param, 2, &uri_len);

        app_bt_pan_set_http(ip_str, ip_str_len, port, uri, uri_len);

        action = BT_PAN_DEMO_ACTION_HTTP;
    }
    else if (!strcmp(subcmd, "sockets"))
    {
#include "pan_test/sockets.h"

        uint32_t param_idx = 0;

        char *mode_str = (char *)cli_param_get(p_param, param_idx++, &param_len);
        app_bt_pan_sockets_set_mode(mode_str);

        if (app_bt_pan_sockets_get_mode() == APP_BT_PAN_SOCKETS_CLIENT)
        {
            char *ip_str = (char *)cli_param_get(p_param, param_idx++, &param_len);
            app_bt_pan_sockets_set_ip_str(ip_str, param_len);
        }

        uint16_t port = (uint16_t)strtol(cli_param_get(p_param, param_idx++, &param_len), NULL, 0);
        app_bt_pan_sockets_set_port(port);

        action = BT_PAN_DEMO_ACTION_SOCKETS;
    }
    else if (!strcmp(subcmd, "sem"))
    {
        action = BT_PAN_DEMO_ACTION_SEM;
    }
    else if (!strcmp(subcmd, "https"))
    {
        action = BT_PAN_DEMO_ACTION_HTTPS_CLIENT;
    }
    else
    {
        goto err;
    }

    param_buf = malloc(40);
    if (param_buf != NULL)
    {
        uint8_t    *p;

        p = param_buf;
        LE_UINT16_TO_STREAM(p, PAN_ID);
        LE_UINT8_TO_STREAM(p, action);

        if (action == BT_PAN_DEMO_ACTION_PAN_CONNECT)
        {
            ARRAY_TO_STREAM(p, addr, 6);
        }

        if (app_bt_pan_demo_send_msg(IO_MSG_CONSOLE_STRING_RX, param_buf) == false)
        {
            free(param_buf);
            goto err;
        }

        snprintf(buf, buf_len, "PAN %s from bt pan demo.\r\n", subcmd);
    }

    return false;

err:
    snprintf(buf, buf_len, "Invalid param %s (pan connect/disconnect).\r\n", subcmd);
    return false;
}

static T_CLI_CMD bt_pan_demo_cmd =
{
    NULL,           /* Next command pointed to NULL. */
    NULL,           /* Next subcommand. */
    "pan",         /* The command string to type. */
    "\r\npan:\r\n bt pan demo start\r\n\r\n",
    console_pan,   /* The function to run. */
    -1              /* Zero or more parameters are expected. */
};

void app_bt_pan_demo_cmd_register(void)
{
    cli_cmd_register(&bt_pan_demo_cmd);
}
```

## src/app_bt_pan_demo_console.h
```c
/*
 * Copyright (c) 2026, Realtek Semiconductor Corporation
 *
 * SPDX-License-Identifier: LicenseRef-Realtek-5-Clause
 */

#ifndef _BT_PAN_DEMO_CONSOLE_H_
#define _BT_PAN_DEMO_CONSOLE_H_

#ifdef __cplusplus
extern "C" {
#endif /* __cplusplus */

/** @defgroup APP_BT_PAN_DEMO_CONSOLE BT PAN Demo Console
* @brief BT PAN Demo command
* @{
*/

typedef enum
{
    GAP_ID = 0x0001,
    PAN_ID = 0x0002,
} T_BT_PAN_DEMO_CMD_ID;

#define BT_PAN_DEMO_ACTION_PAN_CONNECT                    0x01
#define BT_PAN_DEMO_ACTION_PAN_DISCONNECT                 0x02
#define BT_PAN_DEMO_ACTION_PAN_SETUP_CONN_RSP             0x03
#define BT_PAN_DEMO_ACTION_PAN_NET_TYPE_FILTER_SET        0x04
#define BT_PAN_DEMO_ACTION_PAN_MULTI_ADDR_FILTER_SET      0x05
#define BT_PAN_DEMO_ACTION_PAN_SNED_GENERAL               0x06
#define BT_PAN_DEMO_ACTION_PAN_SNED_COMPRESSED            0x07
#define BT_PAN_DEMO_ACTION_PAN_SNED_SRC_ONLY              0x08
#define BT_PAN_DEMO_ACTION_PAN_SNED_DST_ONLY              0x09
#define BT_PAN_DEMO_ACTION_PAN_ARP                        0x0a
#define BT_PAN_DEMO_ACTION_PAN_ARP_V6                     0x0b
#define BT_PAN_DEMO_ACTION_PAN_PING                       0x0c
#define BT_PAN_DEMO_ACTION_PAN_PING_V6                    0x0d
#define BT_PAN_DEMO_ACTION_PAN_PING_REPLY                 0x0e
#define BT_PAN_DEMO_ACTION_PAN_PING_REPLY_V6              0x0f
#define BT_PAN_DEMO_ACTION_HTTP                           0x10
#define BT_PAN_DEMO_ACTION_SOCKETS                        0x11
#define BT_PAN_DEMO_ACTION_SEM                            0x12
#define BT_PAN_DEMO_ACTION_HTTPS_CLIENT                   0x13


void app_bt_pan_demo_cmd_register(void);

/** @} End of APP_BT_PAN_DEMO_CONSOLE */

#ifdef __cplusplus
}
#endif /* __cplusplus */

#endif /* _BT_PAN_DEMO_CONSOLE_H_ */
```

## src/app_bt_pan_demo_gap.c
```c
/*
 * Copyright (c) 2026, Realtek Semiconductor Corporation
 *
 * SPDX-License-Identifier: LicenseRef-Realtek-5-Clause
 */

#include <string.h>
#include "trace.h"
#include "gap.h"
#include "btm.h"
#include "gap_br.h"
#include "bt_bond.h"
#include "bt_pan.h"
#include "app_bt_pan_demo_link.h"
#include "app_bt_pan_demo_gap.h"

static void app_bt_pan_demo_gap_bt_cback(T_BT_EVENT event_type, void *event_buf, uint16_t buf_len)
{
    T_BT_EVENT_PARAM *param = event_buf;
    T_APP_BT_PAN_DEMO_LINK *p_link;
    bool handle = true;

    switch (event_type)
    {
    case BT_EVENT_READY:
        {

        }
        break;

    case BT_EVENT_INQUIRY_RESULT:
        {

        }
        break;

    case BT_EVENT_ACL_CONN_IND:
        {
            p_link = app_bt_pan_demo_find_link(param->acl_conn_ind.bd_addr);
            if (p_link != NULL)
            {
                bt_acl_conn_reject(param->acl_conn_ind.bd_addr, BT_ACL_REJECT_UNACCEPTABLE_ADDR);
            }
            else
            {
                bt_acl_conn_accept(param->acl_conn_ind.bd_addr, BT_LINK_ROLE_SLAVE);
            }

            gap_br_set_radio_mode(GAP_RADIO_MODE_NONE_DISCOVERABLE, false, 0);
        }
        break;

    case BT_EVENT_LINK_KEY_INFO:
        {
            bt_bond_key_set(param->link_key_info.bd_addr, param->link_key_info.link_key,
                            param->link_key_info.key_type);
        }
        break;
    case BT_EVENT_LINK_KEY_REQ:
        {
            uint8_t link_key[16];
            T_BT_LINK_KEY_TYPE type;

            if (bt_bond_key_get(param->link_key_req.bd_addr, link_key, (uint8_t *)&type))
            {
                bt_link_key_cfm(param->link_key_req.bd_addr, true, type, link_key);
            }
            else
            {
                bt_link_key_cfm(param->link_key_req.bd_addr, false, type, link_key);
            }
        }
        break;

    case BT_EVENT_LINK_PIN_CODE_REQ:
        {
            uint8_t pin_code[4] = {1, 2, 3, 4};
            bt_link_pin_code_cfm(param->link_pin_code_req.bd_addr, pin_code, 4, true);
        }
        break;

    case BT_EVENT_LINK_USER_CONFIRMATION_REQ:
        {
            gap_br_user_cfm_req_cfm(param->link_user_confirmation_req.bd_addr, GAP_CFM_CAUSE_ACCEPT);
        }
        break;

    case BT_EVENT_ACL_CONN_SUCCESS:
        {
            app_bt_pan_demo_alloc_link(param->acl_conn_success.bd_addr);
        }
        break;

    case BT_EVENT_ACL_CONN_ENCRYPTED:
        {

        }
        break;


    case BT_EVENT_ACL_CONN_DISCONN:
        {
            p_link = app_bt_pan_demo_find_link(param->acl_conn_disconn.bd_addr);
            if (p_link != NULL)
            {
                app_bt_pan_demo_free_link(p_link);
            }
        }
        break;

    case BT_EVENT_SDP_ATTR_INFO:
        {
            T_BT_SDP_ATTR_INFO *sdp_info = &param->sdp_attr_info.info;
            if (sdp_info->srv_class_uuid_data.uuid_16 == UUID_NAP)
            {
                bt_pan_connect_req(app_db.local_addr, param->sdp_attr_info.bd_addr,
                                   BT_PAN_ROLE_PANU, BT_PAN_ROLE_NAP);
            }
        }
        break;

    default:
        handle = false;
        break;
    }

    if (handle == true)
    {
        APP_PRINT_INFO1("app_bt_pan_demo_gap_bt_cback: event_type 0x%04x", event_type);
    }
}

void app_bt_pan_demo_gap_init(void)
{
    bt_mgr_cback_register(app_bt_pan_demo_gap_bt_cback);
}
```

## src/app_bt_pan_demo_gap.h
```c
/*
 * Copyright (c) 2026, Realtek Semiconductor Corporation
 *
 * SPDX-License-Identifier: LicenseRef-Realtek-5-Clause
 */

#ifndef _BT_PAN_DEMO_GAP_H_
#define _BT_PAN_DEMO_GAP_H_

#ifdef __cplusplus
extern "C" {
#endif /* __cplusplus */

/** @defgroup BT_PAN_DEMO_GAP BT PAN Demo Gap
  * @brief BT PAN Demo Gap
  * @{
  */

/*============================================================================*
 *                              Functions
 *============================================================================*/
void app_bt_pan_demo_gap_init(void);

/** @} End of BT_PAN_DEMO_GAP_Exported_Functions */

/** @} End of BT_PAN_DEMO_GAP */

#ifdef __cplusplus
}
#endif /* __cplusplus */

#endif /* _BT_PAN_DEMO_GAP_H_ */
```

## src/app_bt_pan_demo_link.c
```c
/*
 * Copyright (c) 2026, Realtek Semiconductor Corporation
 *
 * SPDX-License-Identifier: LicenseRef-Realtek-5-Clause
 */

#include <string.h>
#include "app_bt_pan_demo_link.h"

T_APP_BT_PAN_DEMO_APP_DB app_db;

T_APP_BT_PAN_DEMO_LINK *app_bt_pan_demo_find_link(uint8_t *bd_addr)
{
    T_APP_BT_PAN_DEMO_LINK *p_link = NULL;
    uint8_t          i;

    for (i = 0; i < APP_BT_PAN_DEMO_MAX_BR_LINK_NUM; i++)
    {
        if (app_db.br_link[i].used == true &&
            !memcmp(app_db.br_link[i].bd_addr, bd_addr, 6))
        {
            p_link = &app_db.br_link[i];
            break;
        }
    }

    return p_link;
}

T_APP_BT_PAN_DEMO_LINK *app_bt_pan_demo_alloc_link(uint8_t *bd_addr)
{
    T_APP_BT_PAN_DEMO_LINK *p_link = NULL;
    uint8_t        i;

    for (i = 0; i < APP_BT_PAN_DEMO_MAX_BR_LINK_NUM; i++)
    {
        if (app_db.br_link[i].used == false)
        {
            p_link = &app_db.br_link[i];

            p_link->used = true;
            p_link->id   = i;
            memcpy(p_link->bd_addr, bd_addr, 6);
            break;
        }
    }

    return p_link;
}

bool app_bt_pan_demo_free_link(T_APP_BT_PAN_DEMO_LINK *p_link)
{
    if (p_link != NULL)
    {
        if (p_link->used == true)
        {
            memset(p_link, 0, sizeof(T_APP_BT_PAN_DEMO_LINK));
            return true;
        }
    }

    return false;
}
```

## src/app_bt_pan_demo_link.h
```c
/*
 * Copyright (c) 2026, Realtek Semiconductor Corporation
 *
 * SPDX-License-Identifier: LicenseRef-Realtek-5-Clause
 */

#ifndef _APP_BT_PAN_DEMO_LINK_H_
#define _APP_BT_PAN_DEMO_LINK_H_

#include <stdint.h>
#include <stdbool.h>

#ifdef __cplusplus
extern "C" {
#endif /* __cplusplus */

/** @defgroup APP_BT_PAN_DEMO_LINK BT PAN Demo APP Link
  * @brief BT PAN Demo APP Link
  * @{
  */

/*============================================================================*
 *                         Macros
 *============================================================================*/
/** @addtogroup APP_BT_PAN_DEMO_LINK_Exported_Macros BT PAN Demo Link Macros
  * @brief
  * @{
  */

/** @brief  Define links number. range: 0-4 */
#define APP_BT_PAN_DEMO_MAX_BR_LINK_NUM                 4

/** End of APP_BT_PAN_DEMO_LINK_Exported_Macros
* @}
*/

/*============================================================================*
 *                         Types
 *============================================================================*/
/** @defgroup APP_BT_PAN_DEMO_LINK_Exported_Types BT PAN Demo Link Types
  * @brief
  * @{
  */

/**  @brief  APP's Bluetooth BR/EDR link connection database */
typedef struct
{
    uint8_t             bd_addr[6];
    bool                used;
    uint8_t             id;
} T_APP_BT_PAN_DEMO_LINK;

/**  @brief  App define global app data structure */
typedef struct
{
    T_APP_BT_PAN_DEMO_LINK     br_link[APP_BT_PAN_DEMO_MAX_BR_LINK_NUM];
    uint8_t                    local_addr[6];
    uint8_t                    remote_addr[6];
} T_APP_BT_PAN_DEMO_APP_DB;
/** End of APP_BT_PAN_DEMO_LINK_Exported_Types
* @}
*/

extern T_APP_BT_PAN_DEMO_APP_DB app_db;

/*============================================================================*
 *                         Functions
 *============================================================================*/
/** @defgroup APP_BT_PAN_DEMO_LINK_Exported_Functions BT PAN Demo Link Exported Functions
  * @brief
  * @{
  */

/**
 * @brief     Find the APP BT PAN data instance with Remote BT address.
 * @param[in] bd_addr Remote BT address.
 * @return    APP BT PAN data instance. If returned handle is NULL, the APP BT PAN
 *            data instance was failed to create.
 */
T_APP_BT_PAN_DEMO_LINK *app_bt_pan_demo_find_link(uint8_t *bd_addr);

/**
 * @brief     Allocate the APP BT PAN data instance with Remote BT address.
 * @param[in] bd_addr Remote BT address.
 * @return    APP BT PAN data instance. If returned handle is NULL, the APP BT PAN
 *            data instance was failed to create.
 */
T_APP_BT_PAN_DEMO_LINK *app_bt_pan_demo_alloc_link(uint8_t *bd_addr);

/**
 * @brief     Free the APP BT PAN data instance with Remote BT address.
 * @param[in] bd_addr Remote BT address.
 * @return    APP BT PAN data instance. If returned handle is NULL, the APP BT PAN
 *            data instance was failed to create.
 */
bool app_bt_pan_demo_free_link(T_APP_BT_PAN_DEMO_LINK *p_link);

/** @} End of APP_BT_PAN_DEMO_LINK_Exported_Functions */

/** @} End of APP_BT_PAN_DEMO_LINK */

#ifdef __cplusplus
}
#endif /* __cplusplus */

#endif /* _APP_BT_PAN_DEMO_LINK_H_ */
```

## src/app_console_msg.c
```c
/*
 * Copyright (c) 2026, Realtek Semiconductor Corporation
 *
 * SPDX-License-Identifier: LicenseRef-Realtek-5-Clause
 */

#include "trace.h"
#include "bt_types.h"
#include "os_mem.h"
#include "app_msg.h"
#include "app_console_msg.h"
#include "app_bt_pan_demo.h"
#include "app_bt_pan_demo_link.h"
#include "app_bt_pan_demo_console.h"
#include "pan_test/ping.h"
#include "pan_test/http.h"
#include "pan_test/sockets.h"
#include "pan_test/sem.h"
#include "pan_test/https/https_demo.h"


void app_console_handle_msg(T_IO_MSG console_msg)
{
    uint16_t  subtype;
    uint16_t  id;
    uint16_t  action;
    uint8_t  *p;

    p       = console_msg.u.buf;
    subtype = console_msg.subtype;

    APP_PRINT_INFO1("app_console_handle_msg %d", subtype);

    switch (subtype)
    {
    case IO_MSG_CONSOLE_STRING_RX:
        LE_STREAM_TO_UINT16(id, p);
        LE_STREAM_TO_UINT8(action, p);

        if (id == GAP_ID)
        {

        }
        else if (id == PAN_ID)
        {
            switch (action)
            {
            case BT_PAN_DEMO_ACTION_PAN_CONNECT:
                app_bt_pan_demo_connect(p);
                break;

            case BT_PAN_DEMO_ACTION_PAN_DISCONNECT:
                app_bt_pan_demo_disconnect(app_db.remote_addr);
                break;

            case BT_PAN_DEMO_ACTION_PAN_SETUP_CONN_RSP:
                app_bt_pan_demo_setup_onn_rsp(app_db.remote_addr);
                break;

            case BT_PAN_DEMO_ACTION_PAN_NET_TYPE_FILTER_SET:
                app_bt_pan_demo_filter_net_type_set(app_db.remote_addr);
                break;

            case BT_PAN_DEMO_ACTION_PAN_MULTI_ADDR_FILTER_SET:
                app_bt_pan_demo_filter_multi_addr_set(app_db.remote_addr);
                break;

            case BT_PAN_DEMO_ACTION_PAN_SNED_GENERAL:
                app_bt_pan_demo_send(app_db.remote_addr, 0);
                break;

            case BT_PAN_DEMO_ACTION_PAN_SNED_COMPRESSED:
                app_bt_pan_demo_send(app_db.remote_addr, 2);
                break;

            case BT_PAN_DEMO_ACTION_PAN_SNED_SRC_ONLY:
                app_bt_pan_demo_send(app_db.remote_addr, 3);
                break;

            case BT_PAN_DEMO_ACTION_PAN_SNED_DST_ONLY:
                app_bt_pan_demo_send(app_db.remote_addr, 4);
                break;

            case BT_PAN_DEMO_ACTION_PAN_ARP:
                app_bt_pan_demo_arp(app_db.remote_addr);
                break;

            case BT_PAN_DEMO_ACTION_PAN_ARP_V6:
                app_bt_pan_demo_arp_v6(app_db.remote_addr);
                break;

            case BT_PAN_DEMO_ACTION_PAN_PING:
                //app_bt_pan_demo_ping(app_db.remote_addr);
                app_bt_pan_ping();
                break;

            case BT_PAN_DEMO_ACTION_PAN_PING_V6:
                app_bt_pan_demo_ping_v6(app_db.remote_addr);
                break;

            case BT_PAN_DEMO_ACTION_PAN_PING_REPLY:
                app_bt_pan_demo_ping_reply(app_db.remote_addr);
                break;

            case BT_PAN_DEMO_ACTION_PAN_PING_REPLY_V6:
                app_bt_pan_demo_ping_reply_v6(app_db.remote_addr);
                break;

            case BT_PAN_DEMO_ACTION_HTTP:
                app_bt_pan_demo_http();
                break;

            case BT_PAN_DEMO_ACTION_SOCKETS:
                app_bt_pan_sockets();
                break;

            case BT_PAN_DEMO_ACTION_SEM:
                app_bt_pan_sem();
                break;

            case BT_PAN_DEMO_ACTION_HTTPS_CLIENT:
                app_bt_pan_https_client();
                break;

            default:
                break;
            }
        }

        os_mem_free(console_msg.u.buf);
        break;

    default:
        break;
    }
}
```

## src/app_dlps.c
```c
/*
 * Copyright (c) 2026, Realtek Semiconductor Corporation
 *
 * SPDX-License-Identifier: LicenseRef-Realtek-5-Clause
 */

#include "board.h"
#include "trace.h"
#include "pm.h"
#include "io_dlps.h"
#include "section.h"
#include "rtl876x_uart.h"
#include "indirect_access.h"
#include "console_uart.h"

static uint32_t dlps_bitmap;

RAM_TEXT_SECTION void app_dlps_enable(uint32_t bit)
{
    if (dlps_bitmap & bit)
    {
        APP_PRINT_TRACE3("app_dlps_enable: %08x %08x -> %08x", bit, dlps_bitmap,
                         (dlps_bitmap & ~bit));
    }
    dlps_bitmap &= ~bit;
}

RAM_TEXT_SECTION void app_dlps_disable(uint32_t bit)
{
    if ((dlps_bitmap & bit) == 0)
    {
        APP_PRINT_TRACE3("app_dlps_disable: %08x %08x -> %08x", bit, dlps_bitmap,
                         (dlps_bitmap | bit));
    }

    dlps_bitmap |= bit;
}

RAM_TEXT_SECTION bool app_dlps_check_callback(void)
{

    static uint16_t dlps_bitmap_pre;
    bool dlps_enter_en = false;
    if (dlps_bitmap == 0)
    {
        dlps_enter_en = true;
    }

    if (dlps_bitmap_pre != dlps_bitmap)
    {
        APP_PRINT_WARN2("app_dlps_check_callback: dlps_bitmap_pre 0x%x dlps_bitmap 0x%x", dlps_bitmap_pre,
                        dlps_bitmap);
    }
    dlps_bitmap_pre = dlps_bitmap;

    return dlps_enter_en;
}

/**
    * @brief   Need to handle message in this callback function,when App enter dlps mode
    * @param  void
    * @return void
    */
RAM_TEXT_SECTION void app_dlps_enter_callback(void)
{
    POWERMode lps_mode = power_mode_get();

    if ((lps_mode == POWER_POWERDOWN_MODE) || (lps_mode == POWER_SHIP_MODE))
    {
        DBG_DIRECT("app_dlps_enter_callback: lps_mode %d", lps_mode);
    }

}

RAM_TEXT_SECTION void app_dlps_exit_callback(void)
{
    APP_PRINT_INFO4("dump aon reg. 0x126 = 0x%x, 0x128 = 0x%x, 0x130 = 0x%x, 0x132 = 0x%x",
                    btaon_fast_read_safe(0x126), btaon_fast_read_safe(0x128), btaon_fast_read_safe(0x130),
                    btaon_fast_read_safe(0x132));

    console_uart_exit_low_power(power_mode_get());
}

void app_dlps_init(void)
{
    /* register of call back function */
    if (power_check_cb_register(app_dlps_check_callback) != 0)
    {
        APP_PRINT_ERROR0("app_dlps_init: dlps_check_cb_reg failed");
    }

    power_stage_cb_register(app_dlps_enter_callback, POWER_STAGE_STORE);
    power_stage_cb_register(app_dlps_exit_callback, POWER_STAGE_RESTORE);
}
```

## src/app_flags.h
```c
/*
 * Copyright (c) 2026, Realtek Semiconductor Corporation
 *
 * SPDX-License-Identifier: LicenseRef-Realtek-5-Clause
 */

#ifndef _APP_FLAGS_H_
#define _APP_FLAGS_H_

/** @defgroup  BT_HID_DEMO_Config App Configuration
    * @brief This file is used to config app functions.
    * @{
    */
/*============================================================================*
 *                              Constants
 *============================================================================*/

#define F_APP_PAN_PANU_SUPPORT     1
#define F_APP_PAN_NAP_SUPPORT      0
#define F_APP_PAN_GN_SUPPORT       0

#define F_APP_DSP_SHM_80KB_TO_MCU_CHECK_SUPPORT   1

#if (CONFIG_SOC_SERIES_RTL8773D || TARGET_RTL8773DFL || TARGET_RTL87X3EP ||CONFIG_SOC_SERIES_RTL87X3G)
#undef F_APP_DSP_SHM_80KB_TO_MCU_CHECK_SUPPORT
#define F_APP_DSP_SHM_80KB_TO_MCU_CHECK_SUPPORT         0
#endif
/** @} */ /* End of group BT_HID_DEMO_Config */

#endif
```
